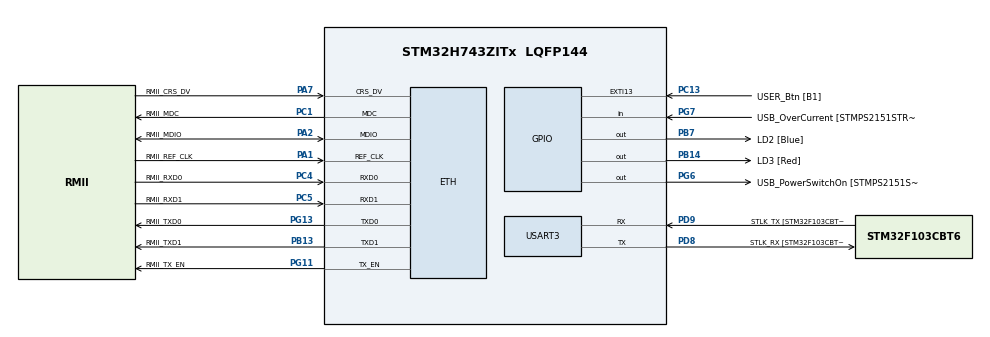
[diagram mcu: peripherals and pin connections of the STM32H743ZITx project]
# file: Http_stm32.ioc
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PB14.GPIO_Label=LD3 [Red]
PG6.GPIO_Label=USB_PowerSwitchOn [STMPS2151STR_EN]
RCC.PLLFRACN=0
PC5.Mode=RMII
PB13.Signal=ETH_TXD1
PG13.Signal=ETH_TXD0
RCC.SYSCLKSource=RCC_SYSCLKSOURCE_PLLCLK
LWIP.NETMASK_ADDRESS=255.255.255.240
LWIP.LWIP_HTTPD=1
USART3.VirtualMode-Asynchronous=VM_ASYNC
RCC.APB2TimFreq_Value=216000000
PD8.Signal=USART3_TX
RCC.DIVM1=1
PC4.GPIO_Label=RMII_RXD0
NVIC.TIM2_IRQn=true\:0\:0\:false\:false\:true\:true\:true
PA8.Signal=USB_OTG_FS_SOF
Mcu.Package=LQFP144
PA10.Signal=USB_OTG_FS_ID
RCC.APB2CLKDivider=RCC_HCLK_DIV2
RCC.APB4Freq_Value=120000000
RCC.APB1TimFreq_Value=108000000
PB13.Mode=RMII
PH0-OSC_IN\ (PH0).Mode=HSE-External-Clock-Source
PC4.Mode=RMII
LWIP.IP_ADDRESS=192.168.006.123
RCC.DIVQ1=20
LWIP0.BSP.i2caddr=0
PD9.GPIO_Label=STLK_TX [STM32F103CBT6_PA2]
PA9.GPIO_Label=USB_VBUS
PC13.Signal=GPXTI13
PA11.GPIO_Label=USB_DM
LWIP.LWIP_DHCP=0
RCC.APB1CLKDivider=RCC_HCLK_DIV4
PG13.GPIO_Label=RMII_TXD0
RCC.PWR_Regulator_Voltage_Scale=PWR_REGULATOR_VOLTAGE_SCALE0
PA8.GPIO_Label=USB_SOF [TP1]
PA9.Signal=USB_OTG_FS_VBUS
RCC.DIVN1=120
PB13.GPIO_Speed=GPIO_SPEED_FREQ_VERY_HIGH
PD8.Mode=Asynchronous
PB14.Signal=GPIO_Output
PA7.GPIO_Speed=GPIO_SPEED_FREQ_LOW
PA1.Mode=RMII
RCC.PRESCALERUSB=RCC_USBCLKSOURCE_PLL_DIV1_5
PG7.GPIO_Label=USB_OverCurrent [STMPS2151STR_FAULT]
PA1.GPIO_Label=RMII_REF_CLK
PC1.GPIO_Speed=GPIO_SPEED_FREQ_VERY_HIGH
ETH.MediaInterface=HAL_ETH_RMII_MODE
PG11.Mode=RMII
PA11.Signal=USB_OTG_FS_DM
ProjectManager.HeapSize=0x200
LWIP.Version=v2.0.3_Cube
NVIC.PriorityGroup=NVIC_PRIORITYGROUP_4
PC5.GPIO_Speed=GPIO_SPEED_FREQ_VERY_HIGH
PC1.Signal=ETH_MDC
PC1.Mode=RMII
Mcu.Family=STM32H7
LWIP0.BSP.STBoard=false
RCC.CortexFreq_Value=480000000
PG6.Signal=GPIO_Output
RCC.HPRE=RCC_HCLK_DIV2
PH0-OSC_IN\ (PH0).Signal=RCC_OSC_IN
RCC.SYSCLKSourceVirtual=RCC_SYSCLKSOURCE_PLLCLK
PA2.GPIO_Speed=GPIO_SPEED_FREQ_VERY_HIGH
PC13.GPIO_Label=USER_Btn [B1]
PB13.GPIO_Label=RMII_TXD1
PD9.Mode=Asynchronous
PG11.Signal=ETH_TX_EN
ProjectManager.StackSize=0x400
PA12.Signal=USB_OTG_FS_DP
RCC.HCLKFreq_Value=240000000
RCC.AHBFreq_Value=216000000
RCC.HSE_VALUE=8000000
RCC.PLLMUL=RCC_PLL_MUL9
PG11.GPIO_Speed=GPIO_SPEED_FREQ_VERY_HIGH
PC4.GPIO_Speed=GPIO_SPEED_FREQ_VERY_HIGH
PA10.GPIO_Label=USB_ID
PB7.Signal=GPIO_Output
PG13.Mode=RMII
LWIP0.BSP.solution=LAN8742
RCC.APB3Freq_Value=120000000
LWIP0.BSP.component=LAN8742
PB7.GPIO_Label=LD2 [Blue]
RCC.D1PPRE=RCC_APB3_DIV2
PA2.GPIO_Label=RMII_MDIO
PG11.GPIO_Label=RMII_TX_EN
PG13.GPIO_Speed=GPIO_SPEED_FREQ_VERY_HIGH
PC5.Signal=ETH_RXD1
RCC.PLLSourceVirtual=RCC_PLLSOURCE_HSE
CORTEX_M7.CPU_ICache=Enabled
PG7.Signal=GPIO_Input
PA7.Mode=RMII
PC4.Signal=ETH_RXD0
RCC.D2PPRE2=RCC_APB2_DIV2
RCC.D2PPRE1=RCC_APB1_DIV2
PD9.Signal=USART3_RX
PA12.GPIO_Label=USB_DP
VP_LWIP_VS_Enabled.Mode=Enabled
PD8.GPIO_Label=STLK_RX [STM32F103CBT6_PA3]
CORTEX_M7.MPU_Control=MPU_HFNMI_PRIVDEF_NONE
ProjectManager.TargetToolchain=TrueSTUDIO
PC15-OSC32_OUT\ (OSC32_OUT).Signal=RCC_OSC32_OUT
LWIP0.BSP.instance=LAN8742
RCC.USBFreq_Value=48000000
LWIP0.BSP.api=BSP_COMPONENT_DRIVER
PA1.Signal=ETH_REF_CLK
board=NUCLEO-H743ZI
RCC.VCOOutputFreq_Value=432000000
RCC.APB2Freq_Value=120000000
VP_TIM2_VS_ClockSourceINT.Mode=Internal
PA1.GPIO_Speed=GPIO_SPEED_FREQ_VERY_HIGH
RCC.ADCFreq_Value=16125000
PC1.GPIO_Label=RMII_MDC
Mcu.Name=STM32H743ZITx
PA2.Signal=ETH_MDIO
RCC.48MHZClocksFreq_Value=24000000
RCC.SYSCLKFreq_VALUE=480000000
PA7.GPIO_Label=RMII_CRS_DV
LWIP.BSP.number=1
PC14-OSC32_IN\ (OSC32_IN).Signal=RCC_OSC32_IN
PC5.GPIO_Label=RMII_RXD1
RCC.HSI_VALUE=64000000
RCC.PLLQ=9
PH0-OSC_IN\ (PH0).GPIO_Label=MCO
RCC.PLLM=25
RCC.PLLN=432
PA2.Mode=RMII
RCC.D3PPRE=RCC_APB4_DIV2
CORTEX_M7.CPU_DCache=Enabled
LWIP0.BSP.name=Driver_PHY
RCC.APB1Freq_Value=120000000
PA7.Signal=ETH_CRS_DV

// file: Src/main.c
/* USER CODE BEGIN Header */
/**
  ******************************************************************************
  * @file           : main.c
  * @brief          : Main program body
  ******************************************************************************
  * @attention
  *
  * <h2><center>&copy; Copyright (c) 2021 STMicroelectronics.
  * All rights reserved.</center></h2>
  *
  * This software component is licensed by ST under Ultimate Liberty license
  * SLA0044, the "License"; You may not use this file except in compliance with
  * the License. You may obtain a copy of the License at:
  *                             www.st.com/SLA0044
  *
  ******************************************************************************
  */
/* USER CODE END Header */

#include "main.h"
#include "lwip.h"

TIM_HandleTypeDef htim2;

UART_HandleTypeDef huart3;

void SystemClock_Config(void);
static void MPU_Config(void);
static void MX_GPIO_Init(void);
static void MX_USART3_UART_Init(void);
static void MX_TIM2_Init(void);

int main(void)
{

  /* MPU Configuration--------------------------------------------------------*/
  MPU_Config();

  /* Enable I-Cache---------------------------------------------------------*/
  SCB_EnableICache();

  /* Enable D-Cache---------------------------------------------------------*/
  SCB_EnableDCache();

  /* MCU Configuration--------------------------------------------------------*/

  /* Reset of all peripherals, Initializes the Flash interface and the Systick. */
  HAL_Init();

  /* Configure the system clock */
  SystemClock_Config();

  /* Initialize all configured peripherals */
  MX_GPIO_Init();
  MX_USART3_UART_Init();
  MX_TIM2_Init();
  /* USER CODE BEGIN 2 */
  HAL_GPIO_TogglePin(LD3_GPIO_Port,LD3_Pin);

  uint16_t go[1000];
sprintf(go,"Hello Mohamed \n\r");
HAL_UART_Transmit(&huart3,go,strlen(go),1000);
MX_LWIP_Init();

  httpd_init();
;
  /* USER CODE END 2 */

  /* Infinite loop */
  /* USER CODE BEGIN WHILE */
  while (1)
  {
	     HAL_GPIO_TogglePin(LD3_GPIO_Port,LD3_Pin);
		 MX_LWIP_Process();
//HAL_Delay(1);
    /* USER CODE END WHILE */

  }
}

void SystemClock_Config(void)
{
  RCC_OscInitTypeDef RCC_OscInitStruct = {0};
  RCC_ClkInitTypeDef RCC_ClkInitStruct = {0};
  RCC_PeriphCLKInitTypeDef PeriphClkInitStruct = {0};

  /** Supply configuration update enable
  */
  HAL_PWREx_ConfigSupply(PWR_LDO_SUPPLY);
  /** Configure the main internal regulator output voltage
  */
  __HAL_PWR_VOLTAGESCALING_CONFIG(PWR_REGULATOR_VOLTAGE_SCALE0);

  while(!__HAL_PWR_GET_FLAG(PWR_FLAG_VOSRDY)) {}
  /** Initializes the CPU, AHB and APB busses clocks
  */
  RCC_OscInitStruct.OscillatorType = RCC_OSCILLATORTYPE_HSE;
  RCC_OscInitStruct.HSEState = RCC_HSE_BYPASS;
  RCC_OscInitStruct.PLL.PLLState = RCC_PLL_ON;
  RCC_OscInitStruct.PLL.PLLSource = RCC_PLLSOURCE_HSE;
  RCC_OscInitStruct.PLL.PLLM = 1;
  RCC_OscInitStruct.PLL.PLLN = 120;
  RCC_OscInitStruct.PLL.PLLP = 2;
  RCC_OscInitStruct.PLL.PLLQ = 20;
  RCC_OscInitStruct.PLL.PLLR = 2;
  RCC_OscInitStruct.PLL.PLLRGE = RCC_PLL1VCIRANGE_3;
  RCC_OscInitStruct.PLL.PLLVCOSEL = RCC_PLL1VCOWIDE;
  RCC_OscInitStruct.PLL.PLLFRACN = 0;
  if (HAL_RCC_OscConfig(&RCC_OscInitStruct) != HAL_OK)
  {
    Error_Handler();
  }
  /** Initializes the CPU, AHB and APB busses clocks
  */
  RCC_ClkInitStruct.ClockType = RCC_CLOCKTYPE_HCLK|RCC_CLOCKTYPE_SYSCLK
                              |RCC_CLOCKTYPE_PCLK1|RCC_CLOCKTYPE_PCLK2
                              |RCC_CLOCKTYPE_D3PCLK1|RCC_CLOCKTYPE_D1PCLK1;
  RCC_ClkInitStruct.SYSCLKSource = RCC_SYSCLKSOURCE_PLLCLK;
  RCC_ClkInitStruct.SYSCLKDivider = RCC_SYSCLK_DIV1;
  RCC_ClkInitStruct.AHBCLKDivider = RCC_HCLK_DIV2;
  RCC_ClkInitStruct.APB3CLKDivider = RCC_APB3_DIV2;
  RCC_ClkInitStruct.APB1CLKDivider = RCC_APB1_DIV2;
  RCC_ClkInitStruct.APB2CLKDivider = RCC_APB2_DIV2;
  RCC_ClkInitStruct.APB4CLKDivider = RCC_APB4_DIV2;

  if (HAL_RCC_ClockConfig(&RCC_ClkInitStruct, FLASH_LATENCY_4) != HAL_OK)
  {
    Error_Handler();
  }
  PeriphClkInitStruct.PeriphClockSelection = RCC_PERIPHCLK_USART3;
  PeriphClkInitStruct.Usart234578ClockSelection = RCC_USART234578CLKSOURCE_D2PCLK1;
  if (HAL_RCCEx_PeriphCLKConfig(&PeriphClkInitStruct) != HAL_OK)
  {
    Error_Handler();
  }
}

static void MX_TIM2_Init(void)
{

  TIM_ClockConfigTypeDef sClockSourceConfig = {0};
  TIM_MasterConfigTypeDef sMasterConfig = {0};

  htim2.Instance = TIM2;
  htim2.Init.Prescaler = 0;
  htim2.Init.CounterMode = TIM_COUNTERMODE_UP;
  htim2.Init.Period = 0;
  htim2.Init.ClockDivision = TIM_CLOCKDIVISION_DIV1;
  htim2.Init.AutoReloadPreload = TIM_AUTORELOAD_PRELOAD_DISABLE;
  if (HAL_TIM_Base_Init(&htim2) != HAL_OK)
  {
    Error_Handler();
  }
  sClockSourceConfig.ClockSource = TIM_CLOCKSOURCE_INTERNAL;
  if (HAL_TIM_ConfigClockSource(&htim2, &sClockSourceConfig) != HAL_OK)
  {
    Error_Handler();
  }
  sMasterConfig.MasterOutputTrigger = TIM_TRGO_RESET;
  sMasterConfig.MasterSlaveMode = TIM_MASTERSLAVEMODE_DISABLE;
  if (HAL_TIMEx_MasterConfigSynchronization(&htim2, &sMasterConfig) != HAL_OK)
  {
    Error_Handler();
  }

}

static void MX_USART3_UART_Init(void)
{

  huart3.Instance = USART3;
  huart3.Init.BaudRate = 115200;
  huart3.Init.WordLength = UART_WORDLENGTH_8B;
  huart3.Init.StopBits = UART_STOPBITS_1;
  huart3.Init.Parity = UART_PARITY_NONE;
  huart3.Init.Mode = UART_MODE_TX_RX;
  huart3.Init.HwFlowCtl = UART_HWCONTROL_NONE;
  huart3.Init.OverSampling = UART_OVERSAMPLING_16;
  huart3.Init.OneBitSampling = UART_ONE_BIT_SAMPLE_DISABLE;
  huart3.Init.ClockPrescaler = UART_PRESCALER_DIV1;
  huart3.AdvancedInit.AdvFeatureInit = UART_ADVFEATURE_NO_INIT;
  if (HAL_UART_Init(&huart3) != HAL_OK)
  {
    Error_Handler();
  }
  if (HAL_UARTEx_SetTxFifoThreshold(&huart3, UART_TXFIFO_THRESHOLD_1_8) != HAL_OK)
  {
    Error_Handler();
  }
  if (HAL_UARTEx_SetRxFifoThreshold(&huart3, UART_RXFIFO_THRESHOLD_1_8) != HAL_OK)
  {
    Error_Handler();
  }
  if (HAL_UARTEx_DisableFifoMode(&huart3) != HAL_OK)
  {
    Error_Handler();
  }

}

static void MX_GPIO_Init(void)
{
  GPIO_InitTypeDef GPIO_InitStruct = {0};

  /* GPIO Ports Clock Enable */
  __HAL_RCC_GPIOC_CLK_ENABLE();
  __HAL_RCC_GPIOH_CLK_ENABLE();
  __HAL_RCC_GPIOA_CLK_ENABLE();
  __HAL_RCC_GPIOB_CLK_ENABLE();
  __HAL_RCC_GPIOD_CLK_ENABLE();
  __HAL_RCC_GPIOG_CLK_ENABLE();

  /*Configure GPIO pin Output Level */
  HAL_GPIO_WritePin(GPIOB, LD3_Pin|LD2_Pin, GPIO_PIN_RESET);

  /*Configure GPIO pin Output Level */
  HAL_GPIO_WritePin(USB_PowerSwitchOn_GPIO_Port, USB_PowerSwitchOn_Pin, GPIO_PIN_RESET);

  /*Configure GPIO pin : USER_Btn_Pin */
  GPIO_InitStruct.Pin = USER_Btn_Pin;
  GPIO_InitStruct.Mode = GPIO_MODE_IT_RISING;
  GPIO_InitStruct.Pull = GPIO_NOPULL;
  HAL_GPIO_Init(USER_Btn_GPIO_Port, &GPIO_InitStruct);

  /*Configure GPIO pins : LD3_Pin LD2_Pin */
  GPIO_InitStruct.Pin = LD3_Pin|LD2_Pin;
  GPIO_InitStruct.Mode = GPIO_MODE_OUTPUT_PP;
  GPIO_InitStruct.Pull = GPIO_NOPULL;
  GPIO_InitStruct.Speed = GPIO_SPEED_FREQ_LOW;
  HAL_GPIO_Init(GPIOB, &GPIO_InitStruct);

  /*Configure GPIO pin : USB_PowerSwitchOn_Pin */
  GPIO_InitStruct.Pin = USB_PowerSwitchOn_Pin;
  GPIO_InitStruct.Mode = GPIO_MODE_OUTPUT_PP;
  GPIO_InitStruct.Pull = GPIO_NOPULL;
  GPIO_InitStruct.Speed = GPIO_SPEED_FREQ_LOW;
  HAL_GPIO_Init(USB_PowerSwitchOn_GPIO_Port, &GPIO_InitStruct);

  /*Configure GPIO pin : USB_OverCurrent_Pin */
  GPIO_InitStruct.Pin = USB_OverCurrent_Pin;
  GPIO_InitStruct.Mode = GPIO_MODE_INPUT;
  GPIO_InitStruct.Pull = GPIO_NOPULL;
  HAL_GPIO_Init(USB_OverCurrent_GPIO_Port, &GPIO_InitStruct);

  /*Configure GPIO pins : USB_SOF_Pin USB_ID_Pin USB_DM_Pin USB_DP_Pin */
  GPIO_InitStruct.Pin = USB_SOF_Pin|USB_ID_Pin|USB_DM_Pin|USB_DP_Pin;
  GPIO_InitStruct.Mode = GPIO_MODE_AF_PP;
  GPIO_InitStruct.Pull = GPIO_NOPULL;
  GPIO_InitStruct.Speed = GPIO_SPEED_FREQ_LOW;
  GPIO_InitStruct.Alternate = GPIO_AF10_OTG1_FS;
  HAL_GPIO_Init(GPIOA, &GPIO_InitStruct);

}

/* MPU Configuration */

void MPU_Config(void)
{

	  MPU_Region_InitTypeDef MPU_InitStruct = {0};

	  /* Disables the MPU */
	  HAL_MPU_Disable();
	  /**Initializes and configures the Region and the memory to be protected
	  */
	  MPU_InitStruct.Enable = MPU_REGION_ENABLE;
	  MPU_InitStruct.Number = MPU_REGION_NUMBER0;
	  MPU_InitStruct.BaseAddress = 0x30040000;
	  MPU_InitStruct.Size = MPU_REGION_SIZE_256B;
	  MPU_InitStruct.SubRegionDisable = 0x0;
	  MPU_InitStruct.TypeExtField = MPU_TEX_LEVEL0;
	  MPU_InitStruct.AccessPermission = MPU_REGION_FULL_ACCESS;
	  MPU_InitStruct.DisableExec = MPU_INSTRUCTION_ACCESS_ENABLE;
	  MPU_InitStruct.IsShareable = MPU_ACCESS_NOT_SHAREABLE;
	  MPU_InitStruct.IsCacheable = MPU_ACCESS_NOT_CACHEABLE;
	  MPU_InitStruct.IsBufferable = MPU_ACCESS_BUFFERABLE;

	  HAL_MPU_ConfigRegion(&MPU_InitStruct);
	  /**Initializes and configures the Region and the memory to be protected
	  */
	  MPU_InitStruct.Enable = MPU_REGION_ENABLE;
	  MPU_InitStruct.Number = MPU_REGION_NUMBER1;
	  MPU_InitStruct.BaseAddress = 0x30044000;
	  MPU_InitStruct.Size = MPU_REGION_SIZE_16KB;
	  MPU_InitStruct.SubRegionDisable = 0x0;
	  MPU_InitStruct.TypeExtField = MPU_TEX_LEVEL0;
	  MPU_InitStruct.AccessPermission = MPU_REGION_NO_ACCESS;
	  MPU_InitStruct.DisableExec = MPU_INSTRUCTION_ACCESS_ENABLE;
	  MPU_InitStruct.IsShareable = MPU_ACCESS_NOT_SHAREABLE;
	  MPU_InitStruct.IsCacheable = MPU_ACCESS_CACHEABLE;
	  MPU_InitStruct.IsBufferable = MPU_ACCESS_NOT_BUFFERABLE;

	  HAL_MPU_ConfigRegion(&MPU_InitStruct);
	  /* Enables the MPU */
	  HAL_MPU_Enable(MPU_PRIVILEGED_DEFAULT);

}

void Error_Handler(void)
{
}

/************************ (C) COPYRIGHT STMicroelectronics *****END OF FILE****/
